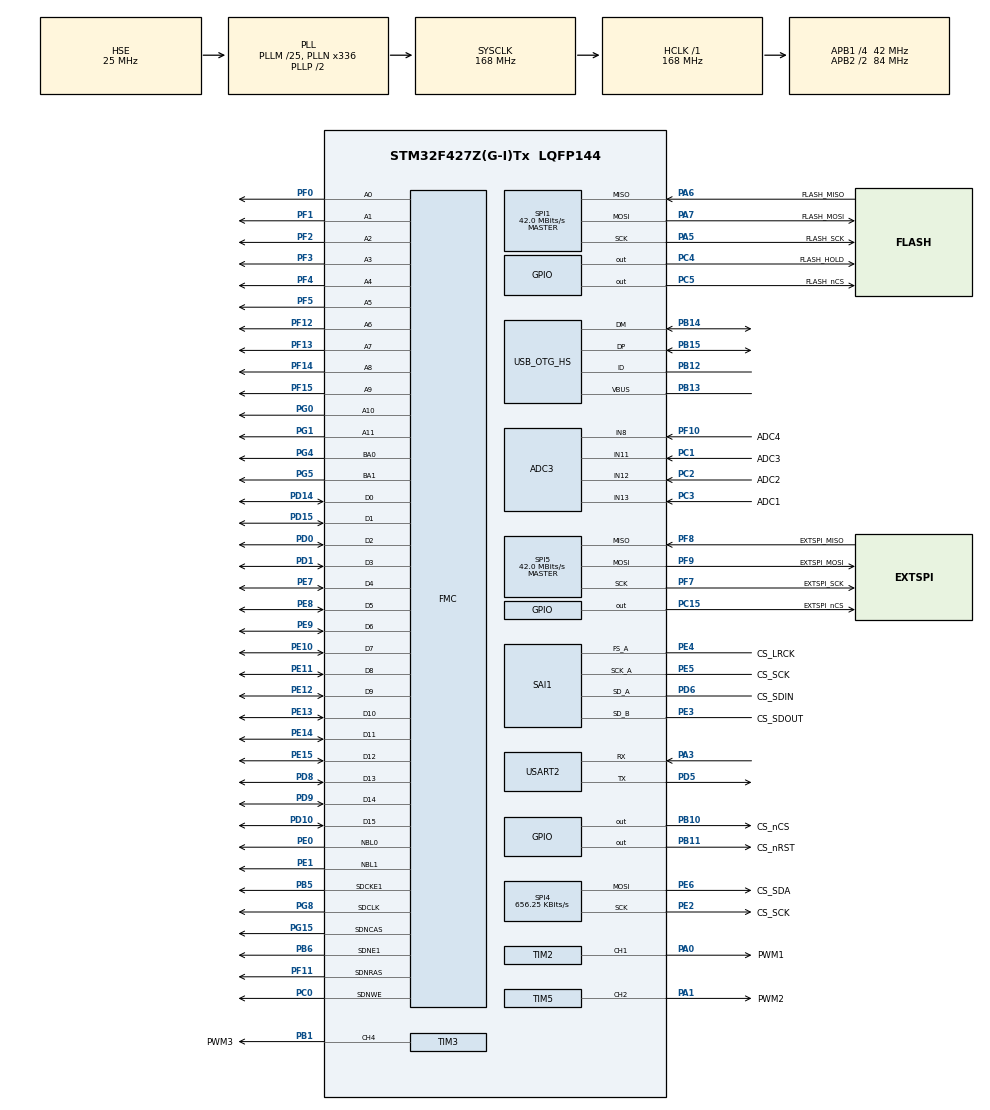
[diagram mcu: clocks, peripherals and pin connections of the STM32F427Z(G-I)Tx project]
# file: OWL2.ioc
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ADC3.Channel-31\#ChannelRegularConversion=ADC_CHANNEL_8
ADC3.ContinuousConvMode=ENABLE
ADC3.DMAContinuousRequests=ENABLE
ADC3.EOCSelection=ADC_EOC_SEQ_CONV
ADC3.EnableAnalogWatchDog=false
ADC3.InjNumberOfConversion=0
ADC3.NbrOfConversionFlag=1
ADC3.Rank-31\#ChannelRegularConversion=1
ADC3.SamplingTime-31\#ChannelRegularConversion=ADC_SAMPLETIME_3CYCLES
ADC3.ScanConvMode=ENABLE
Dma.ADC3.0.Direction=DMA_PERIPH_TO_MEMORY
Dma.ADC3.0.FIFOMode=DMA_FIFOMODE_DISABLE
Dma.ADC3.0.Instance=DMA2_Stream0
Dma.ADC3.0.MemDataAlignment=DMA_MDATAALIGN_HALFWORD
Dma.ADC3.0.MemInc=DMA_MINC_ENABLE
Dma.ADC3.0.Mode=DMA_NORMAL
Dma.ADC3.0.PeriphDataAlignment=DMA_PDATAALIGN_HALFWORD
Dma.ADC3.0.PeriphInc=DMA_PINC_DISABLE
Dma.ADC3.0.Priority=DMA_PRIORITY_LOW
Dma.Request0=ADC3
Dma.Request1=SAI1_A
Dma.Request2=SAI1_B
Dma.SAI1_A.1.Direction=DMA_PERIPH_TO_MEMORY
Dma.SAI1_A.1.FIFOMode=DMA_FIFOMODE_DISABLE
Dma.SAI1_A.1.Instance=DMA2_Stream1
Dma.SAI1_A.1.MemDataAlignment=DMA_MDATAALIGN_WORD
Dma.SAI1_A.1.MemInc=DMA_MINC_ENABLE
Dma.SAI1_A.1.Mode=DMA_NORMAL
Dma.SAI1_A.1.PeriphDataAlignment=DMA_PDATAALIGN_WORD
Dma.SAI1_A.1.PeriphInc=DMA_PINC_DISABLE
Dma.SAI1_A.1.Priority=DMA_PRIORITY_VERY_HIGH
Dma.SAI1_B.2.Direction=DMA_MEMORY_TO_PERIPH
Dma.SAI1_B.2.FIFOMode=DMA_FIFOMODE_DISABLE
Dma.SAI1_B.2.Instance=DMA2_Stream4
Dma.SAI1_B.2.MemDataAlignment=DMA_MDATAALIGN_WORD
Dma.SAI1_B.2.MemInc=DMA_MINC_ENABLE
Dma.SAI1_B.2.Mode=DMA_NORMAL
Dma.SAI1_B.2.PeriphDataAlignment=DMA_PDATAALIGN_WORD
Dma.SAI1_B.2.PeriphInc=DMA_PINC_DISABLE
Dma.SAI1_B.2.Priority=DMA_PRIORITY_VERY_HIGH
FMC.CASLatency1=FMC_SDRAM_CAS_LATENCY_3
FMC.ExitSelfRefreshDelay1=6
FMC.LoadToActiveDelay1=2
FMC.RCDDelay1=2
FMC.RPDelay1=2
FMC.RPDelay2=2
FMC.ReadBurst1=FMC_SDRAM_RBURST_ENABLE
FMC.ReadBurst2=FMC_SDRAM_RBURST_ENABLE
FMC.ReadPipeDelay1=FMC_SDRAM_RPIPE_DELAY_0
FMC.RowCycleDelay1=2
FMC.RowCycleDelay2=2
FMC.SDClockPeriod1=FMC_SDRAM_CLOCK_PERIOD_2
FMC.SDClockPeriod2=FMC_SDRAM_CLOCK_PERIOD_2
FMC.SelfRefreshTime1=4
FMC.WriteRecoveryTime1=2
Mcu.Family=STM32F4
Mcu.Name=STM32F427Z(G-I)Tx
Mcu.Package=LQFP144
NVIC.DMA2_Stream0_IRQn=true\:0\:0\:false\:false\:true
NVIC.DMA2_Stream1_IRQn=true\:0\:0\:false\:false\:true
NVIC.DMA2_Stream4_IRQn=true\:0\:0\:false\:false\:true
NVIC.PriorityGroup=NVIC_PRIORITYGROUP_4
PA0/WKUP.GPIO_Label=PWM1
PA0/WKUP.Signal=S_TIM2_CH1_ETR
PA1.GPIO_Label=PWM2
PA1.Signal=S_TIM5_CH2
PA13.Mode=Trace_Asynchronous_SW
PA13.Signal=SYS_JTMS-SWDIO
PA14.Mode=Trace_Asynchronous_SW
PA14.Signal=SYS_JTCK-SWCLK
PA3.Mode=Asynchronous
PA3.Signal=USART2_RX
PA5.GPIO_Label=FLASH_SCK
PA5.Mode=Full_Duplex_Master
PA5.Signal=SPI1_SCK
PA6.GPIO_Label=FLASH_MISO
PA6.Mode=Full_Duplex_Master
PA6.Signal=SPI1_MISO
PA7.GPIO_Label=FLASH_MOSI
PA7.Mode=Full_Duplex_Master
PA7.Signal=SPI1_MOSI
PB1.GPIO_Label=PWM3
PB1.Signal=S_TIM3_CH4
PB10.GPIO_Label=CS_nCS
PB10.Signal=GPIO_Output
PB11.GPIO_Label=CS_nRST
PB11.Signal=GPIO_Output
PB12.Mode=OTG/Dual-Role-Device-FS
PB12.Signal=USB_OTG_HS_ID
PB13.Mode=Activate_VBUS_FS
PB13.Signal=USB_OTG_HS_VBUS
PB14.Mode=OTG/Dual-Role-Device-FS
PB14.Signal=USB_OTG_HS_DM
PB15.Mode=OTG/Dual-Role-Device-FS
PB15.Signal=USB_OTG_HS_DP
PB3.Mode=Trace_Asynchronous_SW
PB3.Signal=SYS_JTDO-SWO
PB5.Mode=SdramChipSelect2_1
PB5.Signal=FMC_SDCKE1
PB6.Mode=SdramChipSelect2_1
PB6.Signal=FMC_SDNE1
PC0.Signal=FMC_SDNWE
PC1.GPIO_Label=ADC3
PC1.Signal=ADCx_IN11
PC15/OSC32_OUT.GPIO_Label=EXTSPI_nCS
PC15/OSC32_OUT.Signal=GPIO_Output
PC2.GPIO_Label=ADC2
PC2.Signal=ADCx_IN12
PC3.GPIO_Label=ADC1
PC3.Signal=ADCx_IN13
PC4.GPIO_Label=FLASH_HOLD
PC4.Signal=GPIO_Output
PC5.GPIO_Label=FLASH_nCS
PC5.Signal=GPIO_Output
PD0.Signal=FMC_D2_DA2
PD1.Signal=FMC_D3_DA3
PD10.Signal=FMC_D15_DA15
PD14.Signal=FMC_D0_DA0
PD15.Signal=FMC_D1_DA1
PD5.Mode=Asynchronous
PD5.Signal=USART2_TX
PD6.GPIO_Label=CS_SDIN
PD6.Mode=SAI_A_AsyncSlave
PD6.Signal=SAI1_SD_A
PD8.Signal=FMC_D13_DA13
PD9.Signal=FMC_D14_DA14
PE0.Signal=FMC_NBL0
PE1.Signal=FMC_NBL1
PE10.Signal=FMC_D7_DA7
PE11.Signal=FMC_D8_DA8
PE12.Signal=FMC_D9_DA9
PE13.Signal=FMC_D10_DA10
PE14.Signal=FMC_D11_DA11
PE15.Signal=FMC_D12_DA12
PE2.GPIO_Label=CS_SCK
PE2.Mode=TX_Only_Simplex_Unidirect_Master
PE2.Signal=SPI4_SCK
PE3.GPIO_Label=CS_SDOUT
PE3.Mode=SAI_B_SyncSlave
PE3.Signal=SAI1_SD_B
PE4.GPIO_Label=CS_LRCK
PE4.Mode=SAI_A_AsyncSlave
PE4.Signal=SAI1_FS_A
PE5.GPIO_Label=CS_SCK
PE5.Mode=SAI_A_AsyncSlave
PE5.Signal=SAI1_SCK_A
PE6.GPIO_Label=CS_SDA
PE6.Mode=TX_Only_Simplex_Unidirect_Master
PE6.Signal=SPI4_MOSI
PE7.Signal=FMC_D4_DA4
PE8.Signal=FMC_D5_DA5
PE9.Signal=FMC_D6_DA6
PF0.Signal=FMC_A0
PF1.Signal=FMC_A1
PF10.GPIO_Label=ADC4
PF10.Mode=IN8
PF10.Signal=ADC3_IN8
PF11.Signal=FMC_SDNRAS
PF12.Signal=FMC_A6
PF13.Signal=FMC_A7
PF14.Signal=FMC_A8
PF15.Signal=FMC_A9
PF2.Signal=FMC_A2
PF3.Signal=FMC_A3
PF4.Signal=FMC_A4
PF5.Signal=FMC_A5
PF7.GPIO_Label=EXTSPI_SCK
PF7.Mode=Full_Duplex_Master
PF7.Signal=SPI5_SCK
PF8.GPIO_Label=EXTSPI_MISO
PF8.Mode=Full_Duplex_Master
PF8.Signal=SPI5_MISO
PF9.GPIO_Label=EXTSPI_MOSI
PF9.Mode=Full_Duplex_Master
PF9.Signal=SPI5_MOSI
PG0.Signal=FMC_A10
PG1.Signal=FMC_A11
PG15.Signal=FMC_SDNCAS
PG4.Signal=FMC_A14_BA0
PG5.Signal=FMC_A15_BA1
PG8.Signal=FMC_SDCLK
PH0/OSC_IN.Mode=HSE-External-Oscillator
PH0/OSC_IN.Signal=RCC_OSC_IN
PH1/OSC_OUT.Mode=HSE-External-Oscillator
PH1/OSC_OUT.Signal=RCC_OSC_OUT
ProjectManager.HeapSize=0x200
ProjectManager.StackSize=0x400
ProjectManager.TargetToolchain=MDK-ARM V5
RCC.48MHZClocksFreq_Value=48000000
RCC.AHBFreq_Value=168000000
RCC.APB1CLKDivider=RCC_HCLK_DIV4
RCC.APB1Freq_Value=42000000
RCC.APB1TimFreq_Value=84000000
RCC.APB2CLKDivider=RCC_HCLK_DIV2
RCC.APB2Freq_Value=84000000
RCC.APB2TimFreq_Value=168000000
RCC.CortexFreq_Value=168000000
RCC.HCLKFreq_Value=168000000
RCC.HSE_VALUE=25000000
RCC.HSI_VALUE=16000000
RCC.LSE_VALUE=32768
RCC.PLLM=25
RCC.PLLN=336
RCC.PLLQ=7
RCC.PLLSAIN=100
RCC.SYSCLKFreq_VALUE=168000000
RCC.SYSCLKSource=RCC_SYSCLKSOURCE_PLLCLK
RCC.USBFreq_Value=48000000
RCC.VCOOutputFreq_Value=336000000
SAI1.AudioMode-SAI_B_SyncSlave=SAI_MODESLAVE_TX
SAI1.FrameLength-SAI_B_SyncSlave=24
SAI1.Instance-SAI_A_AsyncSlave=SAI$Index_Block_A
SAI1.Instance-SAI_B_SyncSlave=SAI$Index_Block_B
SAI1.Protocol-SAI_B_SyncSlave=SAI_FREE_PROTOCOL
SAI1.SlotActive-SAI_A_AsyncSlave=0x00000000
SAI1.SlotActive-SAI_B_SyncSlave=0x00000000
SAI1.SlotSize-SAI_B_SyncSlave=SAI_SLOTSIZE_DATASIZE
SAI1.Synchro-SAI_B_SyncSlave=SAI_SYNCHRONOUS
SAI1.VirtualMode-SAI_A_AsyncSlave=VM_SLAVE
SAI1.VirtualMode-SAI_B_SyncSlave=VM_SLAVE
SH.ADCx_IN11.0=ADC3_IN11,IN11
SH.ADCx_IN12.0=ADC3_IN12,IN12
SH.ADCx_IN13.0=ADC3_IN13,IN13
SH.FMC_A0.0=FMC_A0,12b-sda1
SH.FMC_A1.0=FMC_A1,12b-sda1
SH.FMC_A10.0=FMC_A10,12b-sda1
SH.FMC_A11.0=FMC_A11,12b-sda1
SH.FMC_A14_BA0.0=FMC_BA0,FourSdramBanks1
SH.FMC_A15_BA1.0=FMC_BA1,FourSdramBanks1
SH.FMC_A2.0=FMC_A2,12b-sda1
SH.FMC_A3.0=FMC_A3,12b-sda1
SH.FMC_A4.0=FMC_A4,12b-sda1
SH.FMC_A5.0=FMC_A5,12b-sda1
SH.FMC_A6.0=FMC_A6,12b-sda1
SH.FMC_A7.0=FMC_A7,12b-sda1
SH.FMC_A8.0=FMC_A8,12b-sda1
SH.FMC_A9.0=FMC_A9,12b-sda1
SH.FMC_D0_DA0.0=FMC_D0,sd-16b-d1
SH.FMC_D10_DA10.0=FMC_D10,sd-16b-d1
SH.FMC_D11_DA11.0=FMC_D11,sd-16b-d1
SH.FMC_D12_DA12.0=FMC_D12,sd-16b-d1
SH.FMC_D13_DA13.0=FMC_D13,sd-16b-d1
SH.FMC_D14_DA14.0=FMC_D14,sd-16b-d1
SH.FMC_D15_DA15.0=FMC_D15,sd-16b-d1
SH.FMC_D1_DA1.0=FMC_D1,sd-16b-d1
SH.FMC_D2_DA2.0=FMC_D2,sd-16b-d1
SH.FMC_D3_DA3.0=FMC_D3,sd-16b-d1
SH.FMC_D4_DA4.0=FMC_D4,sd-16b-d1
SH.FMC_D5_DA5.0=FMC_D5,sd-16b-d1
SH.FMC_D6_DA6.0=FMC_D6,sd-16b-d1
SH.FMC_D7_DA7.0=FMC_D7,sd-16b-d1
SH.FMC_D8_DA8.0=FMC_D8,sd-16b-d1
SH.FMC_D9_DA9.0=FMC_D9,sd-16b-d1
SH.FMC_NBL0.0=FMC_NBL0,Sd2ByteEnable1
SH.FMC_NBL1.0=FMC_NBL1,Sd2ByteEnable1
SH.FMC_SDCLK.0=FMC_SDCLK,12b-sda1
SH.FMC_SDNCAS.0=FMC_SDNCAS,12b-sda1
SH.FMC_SDNRAS.0=FMC_SDNRAS,12b-sda1
SH.FMC_SDNWE.0=FMC_SDNWE,12b-sda1
SH.S_TIM2_CH1_ETR.0=TIM2_CH1,PWM Generation1 CH1
SH.S_TIM3_CH4.0=TIM3_CH4,PWM Generation4 CH4
SH.S_TIM5_CH2.0=TIM5_CH2,PWM Generation2 CH2
SPI1.CalculateBaudRate=42.0 MBits/s
SPI1.Mode=SPI_MODE_MASTER
SPI4.BaudRatePrescaler=SPI_BAUDRATEPRESCALER_128
SPI4.CalculateBaudRate=656.25 KBits/s
SPI4.Mode=SPI_MODE_MASTER
SPI5.CalculateBaudRate=42.0 MBits/s
SPI5.Mode=SPI_MODE_MASTER
TIM2.Period=1000
TIM2.Prescaler=100
TIM3.Channel-PWM\ Generation4\ CH4=TIM_CHANNEL_4
TIM3.Period=1000
TIM3.Prescaler=100
TIM5.Channel-PWM\ Generation2\ CH2=TIM_CHANNEL_2
TIM5.Period=1000
TIM5.Prescaler=100
VP_DMA2D_VS_DMA2D.Mode=DMA2D_Activate
VP_RNG_VS_RNG.Mode=RNG_Activate
board=OWL2

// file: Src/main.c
/**
  ******************************************************************************
  * File Name          : main.c
  * Description        : Main program body
  ******************************************************************************
  *
  * COPYRIGHT(c) 2016 STMicroelectronics
  *
  * Redistribution and use in source and binary forms, with or without modification,
  * are permitted provided that the following conditions are met:
  *   1. Redistributions of source code must retain the above copyright notice,
  *      this list of conditions and the following disclaimer.
  *   2. Redistributions in binary form must reproduce the above copyright notice,
  *      this list of conditions and the following disclaimer in the documentation
  *      and/or other materials provided with the distribution.
  *   3. Neither the name of STMicroelectronics nor the names of its contributors
  *      may be used to endorse or promote products derived from this software
  *      without specific prior written permission.
  *
  * THIS SOFTWARE IS PROVIDED BY THE COPYRIGHT HOLDERS AND CONTRIBUTORS "AS IS"
  * AND ANY EXPRESS OR IMPLIED WARRANTIES, INCLUDING, BUT NOT LIMITED TO, THE
  * IMPLIED WARRANTIES OF MERCHANTABILITY AND FITNESS FOR A PARTICULAR PURPOSE ARE
  * DISCLAIMED. IN NO EVENT SHALL THE COPYRIGHT HOLDER OR CONTRIBUTORS BE LIABLE
  * FOR ANY DIRECT, INDIRECT, INCIDENTAL, SPECIAL, EXEMPLARY, OR CONSEQUENTIAL
  * DAMAGES (INCLUDING, BUT NOT LIMITED TO, PROCUREMENT OF SUBSTITUTE GOODS OR
  * SERVICES; LOSS OF USE, DATA, OR PROFITS; OR BUSINESS INTERRUPTION) HOWEVER
  * CAUSED AND ON ANY THEORY OF LIABILITY, WHETHER IN CONTRACT, STRICT LIABILITY,
  * OR TORT (INCLUDING NEGLIGENCE OR OTHERWISE) ARISING IN ANY WAY OUT OF THE USE
  * OF THIS SOFTWARE, EVEN IF ADVISED OF THE POSSIBILITY OF SUCH DAMAGE.
  *
  ******************************************************************************
  */
#include "stm32f4xx_hal.h"

/* USER CODE BEGIN Includes */
#include "cs4272.h"
#include "HAL_CV.h"

#define REFRESH_COUNT       ((uint32_t)0x0569)   /* SDRAM refresh counter (90MHz SD clock) */

FMC_SDRAM_TimingTypeDef SDRAM_Timing;
FMC_SDRAM_CommandTypeDef command;
void Codec_setup(SPI_HandleTypeDef, SAI_HandleTypeDef, SAI_HandleTypeDef);
void loop(void);

/* #define SDRAM_MEMORY_WIDTH            FMC_SDRAM_MEM_BUS_WIDTH_8 */
#define SDRAM_MEMORY_WIDTH            FMC_SDRAM_MEM_BUS_WIDTH_16

/* #define SDCLOCK_PERIOD                   FMC_SDRAM_CLOCK_PERIOD_2 */
#define SDCLOCK_PERIOD                FMC_SDRAM_CLOCK_PERIOD_3

#define SDRAM_TIMEOUT     											 ((uint32_t)0xFFFF)
#define SDRAM_MODEREG_BURST_LENGTH_1             ((uint16_t)0x0000)
#define SDRAM_MODEREG_BURST_LENGTH_2             ((uint16_t)0x0001)
#define SDRAM_MODEREG_BURST_LENGTH_4             ((uint16_t)0x0002)
#define SDRAM_MODEREG_BURST_LENGTH_8             ((uint16_t)0x0004)
#define SDRAM_MODEREG_BURST_TYPE_SEQUENTIAL      ((uint16_t)0x0000)
#define SDRAM_MODEREG_BURST_TYPE_INTERLEAVED     ((uint16_t)0x0008)
#define SDRAM_MODEREG_CAS_LATENCY_2              ((uint16_t)0x0020)
#define SDRAM_MODEREG_CAS_LATENCY_3              ((uint16_t)0x0030)
#define SDRAM_MODEREG_OPERATING_MODE_STANDARD    ((uint16_t)0x0000)
#define SDRAM_MODEREG_WRITEBURST_MODE_PROGRAMMED ((uint16_t)0x0000)
#define SDRAM_MODEREG_WRITEBURST_MODE_SINGLE     ((uint16_t)0x0200)

static void SDRAM_Initialization_Sequence(SDRAM_HandleTypeDef *hsdram, FMC_SDRAM_CommandTypeDef *Command);
/* USER CODE END Includes */

ADC_HandleTypeDef hadc3;
DMA_HandleTypeDef hdma_adc3;

DMA2D_HandleTypeDef hdma2d;

RNG_HandleTypeDef hrng;

SAI_HandleTypeDef hsai_BlockA1;
SAI_HandleTypeDef hsai_BlockB1;
DMA_HandleTypeDef hdma_sai1_a;
DMA_HandleTypeDef hdma_sai1_b;

SPI_HandleTypeDef hspi1;
SPI_HandleTypeDef hspi4;
SPI_HandleTypeDef hspi5;

TIM_HandleTypeDef htim2;
TIM_HandleTypeDef htim3;
TIM_HandleTypeDef htim5;

UART_HandleTypeDef huart2;

SDRAM_HandleTypeDef hsdram1;

/* USER CODE BEGIN PV */
/* Private variables ---------------------------------------------------------*/

/* USER CODE END PV */

void SystemClock_Config(void);
void Error_Handler(void);
static void MX_GPIO_Init(void);
static void MX_DMA_Init(void);
static void MX_ADC3_Init(void);
static void MX_DMA2D_Init(void);
static void MX_FMC_Init(void);
static void MX_RNG_Init(void);
static void MX_SAI1_Init(void);
static void MX_SPI1_Init(void);
static void MX_SPI4_Init(void);
static void MX_SPI5_Init(void);
static void MX_TIM2_Init(void);
static void MX_TIM3_Init(void);
static void MX_TIM5_Init(void);
static void MX_USART2_UART_Init(void);
static void MX_USB_OTG_HS_USB_Init(void);

void HAL_TIM_MspPostInit(TIM_HandleTypeDef *htim);

/* USER CODE BEGIN PFP */
/* Private function prototypes -----------------------------------------------*/

/* USER CODE END PFP */

int main(void)
{

  /* MCU Configuration----------------------------------------------------------*/

  /* Reset of all peripherals, Initializes the Flash interface and the Systick. */
  HAL_Init();

  /* Configure the system clock */
  SystemClock_Config();

  /* Initialize all configured peripherals */
  MX_GPIO_Init();
  MX_DMA_Init();
  MX_ADC3_Init();
  MX_DMA2D_Init();
  MX_FMC_Init();
  MX_RNG_Init();
  MX_SAI1_Init();
  MX_SPI1_Init();
  MX_SPI4_Init();
  MX_SPI5_Init();
  MX_TIM2_Init();
  MX_TIM3_Init();
  MX_TIM5_Init();
  MX_USART2_UART_Init();
  MX_USB_OTG_HS_USB_Init();

  /* USER CODE BEGIN 2 */
	/* Initialize the SDRAM controller */
	if(HAL_SDRAM_Init(&hsdram1, &SDRAM_Timing) != HAL_OK)
	{
		/* Initialization Error */
		Error_Handler();
	}

	/* Program the SDRAM external device */
	SDRAM_Initialization_Sequence(&hsdram1, &command);

	// Initialise RGB LED
	RGB_init(&htim2, &htim3, &htim5);

	// Initialise CV Sampling
	CV_init(&hadc3);

	// Initialise and start Codec
	Codec_setup(hspi4, hsai_BlockA1, hsai_BlockB1);

  /* USER CODE END 2 */

  /* Infinite loop */
  /* USER CODE BEGIN WHILE */
  while (1)
  {
		loop();

  /* USER CODE END WHILE */

  }

}

/** System Clock Configuration
*/
void SystemClock_Config(void)
{

  RCC_OscInitTypeDef RCC_OscInitStruct;
  RCC_ClkInitTypeDef RCC_ClkInitStruct;
  RCC_PeriphCLKInitTypeDef PeriphClkInitStruct;

  __HAL_RCC_PWR_CLK_ENABLE();

  __HAL_PWR_VOLTAGESCALING_CONFIG(PWR_REGULATOR_VOLTAGE_SCALE1);

  RCC_OscInitStruct.OscillatorType = RCC_OSCILLATORTYPE_HSE;
  RCC_OscInitStruct.HSEState = RCC_HSE_ON;
  RCC_OscInitStruct.PLL.PLLState = RCC_PLL_ON;
  RCC_OscInitStruct.PLL.PLLSource = RCC_PLLSOURCE_HSE;
  RCC_OscInitStruct.PLL.PLLM = 25;
  RCC_OscInitStruct.PLL.PLLN = 336;
  RCC_OscInitStruct.PLL.PLLP = RCC_PLLP_DIV2;
  RCC_OscInitStruct.PLL.PLLQ = 7;
  if (HAL_RCC_OscConfig(&RCC_OscInitStruct) != HAL_OK)
  {
    Error_Handler();
  }

  RCC_ClkInitStruct.ClockType = RCC_CLOCKTYPE_HCLK|RCC_CLOCKTYPE_SYSCLK
                              |RCC_CLOCKTYPE_PCLK1|RCC_CLOCKTYPE_PCLK2;
  RCC_ClkInitStruct.SYSCLKSource = RCC_SYSCLKSOURCE_PLLCLK;
  RCC_ClkInitStruct.AHBCLKDivider = RCC_SYSCLK_DIV1;
  RCC_ClkInitStruct.APB1CLKDivider = RCC_HCLK_DIV4;
  RCC_ClkInitStruct.APB2CLKDivider = RCC_HCLK_DIV2;
  if (HAL_RCC_ClockConfig(&RCC_ClkInitStruct, FLASH_LATENCY_5) != HAL_OK)
  {
    Error_Handler();
  }

  PeriphClkInitStruct.PeriphClockSelection = RCC_PERIPHCLK_SAI_PLLSAI;
  PeriphClkInitStruct.PLLSAI.PLLSAIN = 100;
  PeriphClkInitStruct.PLLSAI.PLLSAIQ = 4;
  PeriphClkInitStruct.PLLSAIDivQ = 1;
  if (HAL_RCCEx_PeriphCLKConfig(&PeriphClkInitStruct) != HAL_OK)
  {
    Error_Handler();
  }

  HAL_SYSTICK_Config(HAL_RCC_GetHCLKFreq()/1000);

  HAL_SYSTICK_CLKSourceConfig(SYSTICK_CLKSOURCE_HCLK);

  /* SysTick_IRQn interrupt configuration */
  HAL_NVIC_SetPriority(SysTick_IRQn, 0, 0);
}

/* ADC3 init function */
static void MX_ADC3_Init(void)
{

  ADC_ChannelConfTypeDef sConfig;

    /**Configure the global features of the ADC (Clock, Resolution, Data Alignment and number of conversion)
    */
  hadc3.Instance = ADC3;
  hadc3.Init.ClockPrescaler = ADC_CLOCK_SYNC_PCLK_DIV4;
  hadc3.Init.Resolution = ADC_RESOLUTION_12B;
  hadc3.Init.ScanConvMode = ENABLE;
  hadc3.Init.ContinuousConvMode = ENABLE;
  hadc3.Init.DiscontinuousConvMode = DISABLE;
  hadc3.Init.ExternalTrigConvEdge = ADC_EXTERNALTRIGCONVEDGE_NONE;
  hadc3.Init.DataAlign = ADC_DATAALIGN_RIGHT;
  hadc3.Init.NbrOfConversion = 4;
  hadc3.Init.DMAContinuousRequests = ENABLE;
  hadc3.Init.EOCSelection = ADC_EOC_SEQ_CONV;
  if (HAL_ADC_Init(&hadc3) != HAL_OK)
  {
    Error_Handler();
  }

    /**Configure for the selected ADC regular channel its corresponding rank in the sequencer and its sample time.
    */
  sConfig.Channel = ADC_CHANNEL_8;
  sConfig.Rank = 1;
  sConfig.SamplingTime = ADC_SAMPLETIME_3CYCLES;
  if (HAL_ADC_ConfigChannel(&hadc3, &sConfig) != HAL_OK)
  {
    Error_Handler();
  }

	sConfig.Channel = ADC_CHANNEL_11;
  sConfig.Rank = 2;
  sConfig.SamplingTime = ADC_SAMPLETIME_3CYCLES;
  if (HAL_ADC_ConfigChannel(&hadc3, &sConfig) != HAL_OK)
  {
    Error_Handler();
  }

	sConfig.Channel = ADC_CHANNEL_12;
  sConfig.Rank = 3;
  sConfig.SamplingTime = ADC_SAMPLETIME_3CYCLES;
  if (HAL_ADC_ConfigChannel(&hadc3, &sConfig) != HAL_OK)
  {
    Error_Handler();
  }

	sConfig.Channel = ADC_CHANNEL_13;
  sConfig.Rank = 4;
  sConfig.SamplingTime = ADC_SAMPLETIME_3CYCLES;
  if (HAL_ADC_ConfigChannel(&hadc3, &sConfig) != HAL_OK)
  {
    Error_Handler();
  }

}

/* DMA2D init function */
static void MX_DMA2D_Init(void)
{

  hdma2d.Instance = DMA2D;
  hdma2d.Init.Mode = DMA2D_M2M;
  hdma2d.Init.ColorMode = DMA2D_OUTPUT_ARGB8888;
  hdma2d.Init.OutputOffset = 0;
  hdma2d.LayerCfg[1].InputOffset = 0;
  hdma2d.LayerCfg[1].InputColorMode = DMA2D_INPUT_ARGB8888;
  hdma2d.LayerCfg[1].AlphaMode = DMA2D_NO_MODIF_ALPHA;
  hdma2d.LayerCfg[1].InputAlpha = 0;
  if (HAL_DMA2D_Init(&hdma2d) != HAL_OK)
  {
    Error_Handler();
  }

  if (HAL_DMA2D_ConfigLayer(&hdma2d, 1) != HAL_OK)
  {
    Error_Handler();
  }

}

/* RNG init function */
static void MX_RNG_Init(void)
{

  hrng.Instance = RNG;
  if (HAL_RNG_Init(&hrng) != HAL_OK)
  {
    Error_Handler();
  }

}

/* SAI1 init function */
static void MX_SAI1_Init(void)
{

  hsai_BlockA1.Instance = SAI1_Block_A;
  hsai_BlockA1.Init.Protocol = SAI_FREE_PROTOCOL;
  hsai_BlockA1.Init.AudioMode = SAI_MODESLAVE_TX;
  hsai_BlockA1.Init.DataSize = SAI_DATASIZE_24;
  hsai_BlockA1.Init.FirstBit = SAI_FIRSTBIT_MSB;
  hsai_BlockA1.Init.ClockStrobing = SAI_CLOCKSTROBING_FALLINGEDGE;
  hsai_BlockA1.Init.Synchro = SAI_ASYNCHRONOUS;
  hsai_BlockA1.Init.OutputDrive = SAI_OUTPUTDRIVE_DISABLE;
  hsai_BlockA1.Init.FIFOThreshold = SAI_FIFOTHRESHOLD_EMPTY;
  hsai_BlockA1.FrameInit.FrameLength = 64;
  hsai_BlockA1.FrameInit.ActiveFrameLength = 32;
  hsai_BlockA1.FrameInit.FSDefinition = SAI_FS_CHANNEL_IDENTIFICATION;
  hsai_BlockA1.FrameInit.FSPolarity = SAI_FS_ACTIVE_LOW;
  hsai_BlockA1.FrameInit.FSOffset = SAI_FS_BEFOREFIRSTBIT;
  hsai_BlockA1.SlotInit.FirstBitOffset = 8;
  hsai_BlockA1.SlotInit.SlotSize = SAI_SLOTSIZE_32B;
  hsai_BlockA1.SlotInit.SlotNumber = 2;
  hsai_BlockA1.SlotInit.SlotActive = SAI_SLOTACTIVE_ALL;
  if (HAL_SAI_Init(&hsai_BlockA1) != HAL_OK)
  {
    Error_Handler();
  }

  hsai_BlockB1.Instance = SAI1_Block_B;
  hsai_BlockB1.Init.Protocol = SAI_FREE_PROTOCOL;
  hsai_BlockB1.Init.AudioMode = SAI_MODESLAVE_RX;
  hsai_BlockB1.Init.DataSize = SAI_DATASIZE_24;
  hsai_BlockB1.Init.FirstBit = SAI_FIRSTBIT_MSB;
  hsai_BlockB1.Init.ClockStrobing = SAI_CLOCKSTROBING_RISINGEDGE;
  hsai_BlockB1.Init.Synchro = SAI_SYNCHRONOUS;
  hsai_BlockB1.Init.OutputDrive = SAI_OUTPUTDRIVE_DISABLE;
  hsai_BlockB1.Init.FIFOThreshold = SAI_FIFOTHRESHOLD_EMPTY;
  hsai_BlockB1.FrameInit.FrameLength = 64;
  hsai_BlockB1.FrameInit.ActiveFrameLength = 32;
  hsai_BlockB1.FrameInit.FSDefinition = SAI_FS_CHANNEL_IDENTIFICATION;
  hsai_BlockB1.FrameInit.FSPolarity = SAI_FS_ACTIVE_LOW;
  hsai_BlockB1.FrameInit.FSOffset = SAI_FS_BEFOREFIRSTBIT;
  hsai_BlockB1.SlotInit.FirstBitOffset = 8;
  hsai_BlockB1.SlotInit.SlotSize = SAI_SLOTSIZE_32B;
  hsai_BlockB1.SlotInit.SlotNumber = 2;
  hsai_BlockB1.SlotInit.SlotActive = SAI_SLOTACTIVE_ALL;
  if (HAL_SAI_Init(&hsai_BlockB1) != HAL_OK)
  {
    Error_Handler();
  }

}

/* SPI1 init function */
static void MX_SPI1_Init(void)
{

  hspi1.Instance = SPI1;
  hspi1.Init.Mode = SPI_MODE_MASTER;
  hspi1.Init.Direction = SPI_DIRECTION_2LINES;
  hspi1.Init.DataSize = SPI_DATASIZE_8BIT;
  hspi1.Init.CLKPolarity = SPI_POLARITY_LOW;
  hspi1.Init.CLKPhase = SPI_PHASE_1EDGE;
  hspi1.Init.NSS = SPI_NSS_SOFT;
  hspi1.Init.BaudRatePrescaler = SPI_BAUDRATEPRESCALER_2;
  hspi1.Init.FirstBit = SPI_FIRSTBIT_MSB;
  hspi1.Init.TIMode = SPI_TIMODE_DISABLE;
  hspi1.Init.CRCCalculation = SPI_CRCCALCULATION_DISABLE;
  hspi1.Init.CRCPolynomial = 10;
  if (HAL_SPI_Init(&hspi1) != HAL_OK)
  {
    Error_Handler();
  }

}

/* SPI4 init function */
static void MX_SPI4_Init(void)
{

  hspi4.Instance = SPI4;
  hspi4.Init.Mode = SPI_MODE_MASTER;
  hspi4.Init.Direction = SPI_DIRECTION_2LINES;
  hspi4.Init.DataSize = SPI_DATASIZE_8BIT;
  hspi4.Init.CLKPolarity = SPI_POLARITY_LOW;
  hspi4.Init.CLKPhase = SPI_PHASE_1EDGE;
  hspi4.Init.NSS = SPI_NSS_SOFT;
  hspi4.Init.BaudRatePrescaler = SPI_BAUDRATEPRESCALER_128;
  hspi4.Init.FirstBit = SPI_FIRSTBIT_MSB;
  hspi4.Init.TIMode = SPI_TIMODE_DISABLE;
  hspi4.Init.CRCCalculation = SPI_CRCCALCULATION_DISABLE;
  hspi4.Init.CRCPolynomial = 10;
  if (HAL_SPI_Init(&hspi4) != HAL_OK)
  {
    Error_Handler();
  }

}

/* SPI5 init function */
static void MX_SPI5_Init(void)
{

  hspi5.Instance = SPI5;
  hspi5.Init.Mode = SPI_MODE_MASTER;
  hspi5.Init.Direction = SPI_DIRECTION_2LINES;
  hspi5.Init.DataSize = SPI_DATASIZE_8BIT;
  hspi5.Init.CLKPolarity = SPI_POLARITY_LOW;
  hspi5.Init.CLKPhase = SPI_PHASE_1EDGE;
  hspi5.Init.NSS = SPI_NSS_SOFT;
  hspi5.Init.BaudRatePrescaler = SPI_BAUDRATEPRESCALER_2;
  hspi5.Init.FirstBit = SPI_FIRSTBIT_MSB;
  hspi5.Init.TIMode = SPI_TIMODE_DISABLE;
  hspi5.Init.CRCCalculation = SPI_CRCCALCULATION_DISABLE;
  hspi5.Init.CRCPolynomial = 10;
  if (HAL_SPI_Init(&hspi5) != HAL_OK)
  {
    Error_Handler();
  }

}

/* TIM2 init function */
static void MX_TIM2_Init(void)
{

  TIM_MasterConfigTypeDef sMasterConfig;
  TIM_OC_InitTypeDef sConfigOC;

  htim2.Instance = TIM2;
  htim2.Init.Prescaler = 100;
  htim2.Init.CounterMode = TIM_COUNTERMODE_UP;
  htim2.Init.Period = 1000;
  htim2.Init.ClockDivision = TIM_CLOCKDIVISION_DIV1;
  if (HAL_TIM_PWM_Init(&htim2) != HAL_OK)
  {
    Error_Handler();
  }

  sMasterConfig.MasterOutputTrigger = TIM_TRGO_RESET;
  sMasterConfig.MasterSlaveMode = TIM_MASTERSLAVEMODE_DISABLE;
  if (HAL_TIMEx_MasterConfigSynchronization(&htim2, &sMasterConfig) != HAL_OK)
  {
    Error_Handler();
  }

  sConfigOC.OCMode = TIM_OCMODE_PWM1;
  sConfigOC.Pulse = 0;
  sConfigOC.OCPolarity = TIM_OCPOLARITY_HIGH;
  sConfigOC.OCFastMode = TIM_OCFAST_DISABLE;
  if (HAL_TIM_PWM_ConfigChannel(&htim2, &sConfigOC, TIM_CHANNEL_1) != HAL_OK)
  {
    Error_Handler();
  }

  HAL_TIM_MspPostInit(&htim2);

}

/* TIM3 init function */
static void MX_TIM3_Init(void)
{

  TIM_MasterConfigTypeDef sMasterConfig;
  TIM_OC_InitTypeDef sConfigOC;

  htim3.Instance = TIM3;
  htim3.Init.Prescaler = 100;
  htim3.Init.CounterMode = TIM_COUNTERMODE_UP;
  htim3.Init.Period = 1000;
  htim3.Init.ClockDivision = TIM_CLOCKDIVISION_DIV1;
  if (HAL_TIM_PWM_Init(&htim3) != HAL_OK)
  {
    Error_Handler();
  }

  sMasterConfig.MasterOutputTrigger = TIM_TRGO_RESET;
  sMasterConfig.MasterSlaveMode = TIM_MASTERSLAVEMODE_DISABLE;
  if (HAL_TIMEx_MasterConfigSynchronization(&htim3, &sMasterConfig) != HAL_OK)
  {
    Error_Handler();
  }

  sConfigOC.OCMode = TIM_OCMODE_PWM1;
  sConfigOC.Pulse = 0;
  sConfigOC.OCPolarity = TIM_OCPOLARITY_HIGH;
  sConfigOC.OCFastMode = TIM_OCFAST_DISABLE;
  if (HAL_TIM_PWM_ConfigChannel(&htim3, &sConfigOC, TIM_CHANNEL_4) != HAL_OK)
  {
    Error_Handler();
  }

  HAL_TIM_MspPostInit(&htim3);

}

/* TIM5 init function */
static void MX_TIM5_Init(void)
{

  TIM_MasterConfigTypeDef sMasterConfig;
  TIM_OC_InitTypeDef sConfigOC;

  htim5.Instance = TIM5;
  htim5.Init.Prescaler = 100;
  htim5.Init.CounterMode = TIM_COUNTERMODE_UP;
  htim5.Init.Period = 1000;
  htim5.Init.ClockDivision = TIM_CLOCKDIVISION_DIV1;
  if (HAL_TIM_PWM_Init(&htim5) != HAL_OK)
  {
    Error_Handler();
  }

  sMasterConfig.MasterOutputTrigger = TIM_TRGO_RESET;
  sMasterConfig.MasterSlaveMode = TIM_MASTERSLAVEMODE_DISABLE;
  if (HAL_TIMEx_MasterConfigSynchronization(&htim5, &sMasterConfig) != HAL_OK)
  {
    Error_Handler();
  }

  sConfigOC.OCMode = TIM_OCMODE_PWM1;
  sConfigOC.Pulse = 0;
  sConfigOC.OCPolarity = TIM_OCPOLARITY_HIGH;
  sConfigOC.OCFastMode = TIM_OCFAST_DISABLE;
  if (HAL_TIM_PWM_ConfigChannel(&htim5, &sConfigOC, TIM_CHANNEL_2) != HAL_OK)
  {
    Error_Handler();
  }

  HAL_TIM_MspPostInit(&htim5);

}

/* USART2 init function */
static void MX_USART2_UART_Init(void)
{

  huart2.Instance = USART2;
  huart2.Init.BaudRate = 115200;
  huart2.Init.WordLength = UART_WORDLENGTH_8B;
  huart2.Init.StopBits = UART_STOPBITS_1;
  huart2.Init.Parity = UART_PARITY_NONE;
  huart2.Init.Mode = UART_MODE_TX_RX;
  huart2.Init.HwFlowCtl = UART_HWCONTROL_NONE;
  huart2.Init.OverSampling = UART_OVERSAMPLING_16;
  if (HAL_UART_Init(&huart2) != HAL_OK)
  {
    Error_Handler();
  }

}

/* USB_OTG_HS init function */
static void MX_USB_OTG_HS_USB_Init(void)
{

}

static void MX_DMA_Init(void)
{
  /* DMA controller clock enable */
  __HAL_RCC_DMA2_CLK_ENABLE();

  /* DMA interrupt init */
  /* DMA2_Stream0_IRQn interrupt configuration */
  HAL_NVIC_SetPriority(DMA2_Stream0_IRQn, 0, 0);
  HAL_NVIC_EnableIRQ(DMA2_Stream0_IRQn);
  /* DMA2_Stream1_IRQn interrupt configuration */
  HAL_NVIC_SetPriority(DMA2_Stream1_IRQn, 0, 0);
  HAL_NVIC_EnableIRQ(DMA2_Stream1_IRQn);
  /* DMA2_Stream4_IRQn interrupt configuration */
  HAL_NVIC_SetPriority(DMA2_Stream4_IRQn, 0, 0);
  HAL_NVIC_EnableIRQ(DMA2_Stream4_IRQn);

}
/* FMC initialization function */
static void MX_FMC_Init(void)
{
  FMC_SDRAM_TimingTypeDef SdramTiming;

  /** Perform the SDRAM1 memory initialization sequence
  */
  hsdram1.Instance = FMC_SDRAM_DEVICE;
  /* hsdram1.Init */
  hsdram1.Init.SDBank = FMC_SDRAM_BANK2;
  hsdram1.Init.ColumnBitsNumber = FMC_SDRAM_COLUMN_BITS_NUM_8;
  hsdram1.Init.RowBitsNumber = FMC_SDRAM_ROW_BITS_NUM_11;
  hsdram1.Init.MemoryDataWidth = FMC_SDRAM_MEM_BUS_WIDTH_16;
  hsdram1.Init.InternalBankNumber = FMC_SDRAM_INTERN_BANKS_NUM_4;
  hsdram1.Init.CASLatency = FMC_SDRAM_CAS_LATENCY_3;
  hsdram1.Init.WriteProtection = FMC_SDRAM_WRITE_PROTECTION_DISABLE;
  hsdram1.Init.SDClockPeriod = FMC_SDRAM_CLOCK_PERIOD_2;
  hsdram1.Init.ReadBurst = FMC_SDRAM_RBURST_ENABLE;
  hsdram1.Init.ReadPipeDelay = FMC_SDRAM_RPIPE_DELAY_0;
  /* SdramTiming */
  SdramTiming.LoadToActiveDelay = 2;
  SdramTiming.ExitSelfRefreshDelay = 6;
  SdramTiming.SelfRefreshTime = 4;
  SdramTiming.RowCycleDelay = 2;
  SdramTiming.WriteRecoveryTime = 2;
  SdramTiming.RPDelay = 2;
  SdramTiming.RCDDelay = 2;

  if (HAL_SDRAM_Init(&hsdram1, &SdramTiming) != HAL_OK)
  {
    Error_Handler();
  }

}

/** Configure pins as
        * Analog
        * Input
        * Output
        * EVENT_OUT
        * EXTI
     PB12   ------> USB_OTG_HS_ID
     PB13   ------> USB_OTG_HS_VBUS
     PB14   ------> USB_OTG_HS_DM
     PB15   ------> USB_OTG_HS_DP
*/
static void MX_GPIO_Init(void)
{

  GPIO_InitTypeDef GPIO_InitStruct;

  /* GPIO Ports Clock Enable */
  __HAL_RCC_GPIOE_CLK_ENABLE();
  __HAL_RCC_GPIOC_CLK_ENABLE();
  __HAL_RCC_GPIOF_CLK_ENABLE();
  __HAL_RCC_GPIOH_CLK_ENABLE();
  __HAL_RCC_GPIOA_CLK_ENABLE();
  __HAL_RCC_GPIOB_CLK_ENABLE();
  __HAL_RCC_GPIOG_CLK_ENABLE();
  __HAL_RCC_GPIOD_CLK_ENABLE();

  /*Configure GPIO pin Output Level */
  HAL_GPIO_WritePin(GPIOC, EXTSPI_nCS_Pin|FLASH_HOLD_Pin|FLASH_nCS_Pin, GPIO_PIN_RESET);

  /*Configure GPIO pin Output Level */
  HAL_GPIO_WritePin(GPIOB, CS_nCS_Pin|CS_nRST_Pin, GPIO_PIN_RESET);

  /*Configure GPIO pins : EXTSPI_nCS_Pin FLASH_HOLD_Pin FLASH_nCS_Pin */
  GPIO_InitStruct.Pin = EXTSPI_nCS_Pin|FLASH_HOLD_Pin|FLASH_nCS_Pin;
  GPIO_InitStruct.Mode = GPIO_MODE_OUTPUT_PP;
  GPIO_InitStruct.Pull = GPIO_NOPULL;
  GPIO_InitStruct.Speed = GPIO_SPEED_FREQ_LOW;
  HAL_GPIO_Init(GPIOC, &GPIO_InitStruct);

  /*Configure GPIO pins : CS_nCS_Pin CS_nRST_Pin */
  GPIO_InitStruct.Pin = CS_nCS_Pin|CS_nRST_Pin;
  GPIO_InitStruct.Mode = GPIO_MODE_OUTPUT_PP;
  GPIO_InitStruct.Pull = GPIO_NOPULL;
  GPIO_InitStruct.Speed = GPIO_SPEED_FREQ_LOW;
  HAL_GPIO_Init(GPIOB, &GPIO_InitStruct);

  /*Configure GPIO pins : PB12 PB14 PB15 */
  GPIO_InitStruct.Pin = GPIO_PIN_12|GPIO_PIN_14|GPIO_PIN_15;
  GPIO_InitStruct.Mode = GPIO_MODE_AF_PP;
  GPIO_InitStruct.Pull = GPIO_NOPULL;
  GPIO_InitStruct.Speed = GPIO_SPEED_FREQ_VERY_HIGH;
  GPIO_InitStruct.Alternate = GPIO_AF12_OTG_HS_FS;
  HAL_GPIO_Init(GPIOB, &GPIO_InitStruct);

  /*Configure GPIO pin : PB13 */
  GPIO_InitStruct.Pin = GPIO_PIN_13;
  GPIO_InitStruct.Mode = GPIO_MODE_INPUT;
  GPIO_InitStruct.Pull = GPIO_NOPULL;
  HAL_GPIO_Init(GPIOB, &GPIO_InitStruct);

}

/* USER CODE BEGIN 4 */
static void SDRAM_Initialization_Sequence(SDRAM_HandleTypeDef *hsdram, FMC_SDRAM_CommandTypeDef *Command)
{
  __IO uint32_t tmpmrd =0;
  /* Step 3:  Configure a clock configuration enable command */
  Command->CommandMode 			 = FMC_SDRAM_CMD_CLK_ENABLE;
  Command->CommandTarget 		 = FMC_SDRAM_CMD_TARGET_BANK2;
  Command->AutoRefreshNumber 	 = 1;
  Command->ModeRegisterDefinition = 0;

  /* Send the command */
  HAL_SDRAM_SendCommand(hsdram, Command, 0x1000);

  /* Step 4: Insert 100 ms delay */
  HAL_Delay(100);

  /* Step 5: Configure a PALL (precharge all) command */
	Command->CommandMode 			 = FMC_SDRAM_CMD_PALL;
  Command->CommandTarget 	     = FMC_SDRAM_CMD_TARGET_BANK2;
  Command->AutoRefreshNumber 	 = 1;
  Command->ModeRegisterDefinition = 0;

  /* Send the command */
  HAL_SDRAM_SendCommand(hsdram, Command, 0x1000);

  /* Step 6 : Configure a Auto-Refresh command */
  Command->CommandMode 			 = FMC_SDRAM_CMD_AUTOREFRESH_MODE;
  Command->CommandTarget 		 = FMC_SDRAM_CMD_TARGET_BANK2;
  Command->AutoRefreshNumber 	 = 4;
  Command->ModeRegisterDefinition = 0;

  /* Send the command */
  HAL_SDRAM_SendCommand(hsdram, Command, 0x1000);

  /* Step 7: Program the external memory mode register */
  tmpmrd = (uint32_t)SDRAM_MODEREG_BURST_LENGTH_2          |
                     SDRAM_MODEREG_BURST_TYPE_SEQUENTIAL   |
                     SDRAM_MODEREG_CAS_LATENCY_3           |
                     SDRAM_MODEREG_OPERATING_MODE_STANDARD |
                     SDRAM_MODEREG_WRITEBURST_MODE_SINGLE;

  Command->CommandMode = FMC_SDRAM_CMD_LOAD_MODE;
  Command->CommandTarget 		 = FMC_SDRAM_CMD_TARGET_BANK2;
  Command->AutoRefreshNumber 	 = 1;
  Command->ModeRegisterDefinition = tmpmrd;

  /* Send the command */
  HAL_SDRAM_SendCommand(hsdram, Command, 0x1000);

  /* Step 8: Set the refresh rate counter */
  /* (15.62 us x Freq) - 20 */
  /* Set the device refresh counter */
  HAL_SDRAM_ProgramRefreshRate(hsdram, REFRESH_COUNT);
}
/* USER CODE END 4 */

void Error_Handler(void)
{
  while(1)
  {
  }
}

/************************ (C) COPYRIGHT STMicroelectronics *****END OF FILE****/
